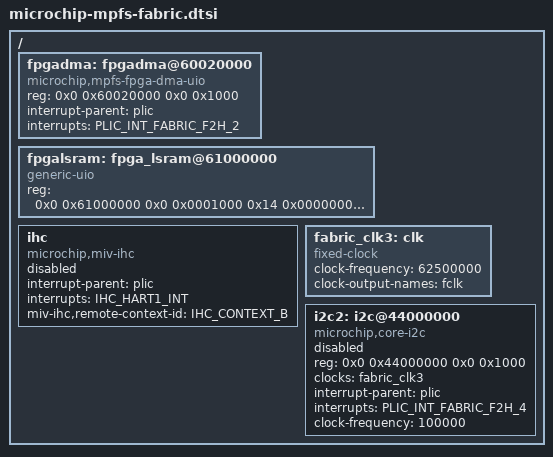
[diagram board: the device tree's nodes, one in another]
// SPDX-License-Identifier: (GPL-2.0 OR MIT)
/* Copyright (c) 2020-2021 Microchip Technology Inc */

/ {
	fpgadma: fpgadma@60020000 {
		compatible = "microchip,mpfs-fpga-dma-uio";
		#address-cells = <1>;
		#size-cells = <0>;
		reg = <0x0 0x60020000 0x0 0x1000>;
		interrupt-parent = <&plic>;
		interrupts = <PLIC_INT_FABRIC_F2H_2>;
		status = "okay";
	};

	fpgalsram: fpga_lsram@61000000 {
		compatible = "generic-uio";
		reg = <0x0 0x61000000 0x0 0x0001000
			0x14 0x00000000 0x0 0x00010000>;
		status = "okay";
	};

	ihc: ihc {
		compatible = "microchip,miv-ihc";
		interrupt-parent = <&plic>;
		interrupts = <IHC_HART1_INT>;
		miv-ihc,remote-context-id = <IHC_CONTEXT_B>;
		#mbox-cells = <1>;
		status = "disabled";
	};

	fabric_clk3: clk {
		compatible = "fixed-clock";
		#clock-cells = <0>;
		clock-frequency = <62500000>;
		clock-output-names = "fclk";
	};

	i2c2: i2c@44000000 {
		compatible = "microchip,core-i2c";
		reg = <0x0 0x44000000 0x0 0x1000>;
		#address-cells = <1>;
		#size-cells = <0>;
		clocks = <&fabric_clk3>;
		interrupt-parent = <&plic>;
		interrupts = <PLIC_INT_FABRIC_F2H_4>;
		clock-frequency = <100000>;
		status = "disabled";
	};
};

